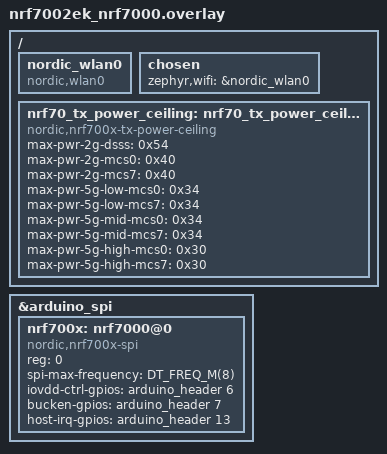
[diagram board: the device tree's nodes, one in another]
/* Copyright (c) 2023 Nordic Semiconductor ASA
 *
 * SPDX-License-Identifier: LicenseRef-Nordic-5-Clause
 */
#include <freq.h>

/ {
        nordic_wlan0: nordic_wlan0 {
                compatible = "nordic,wlan0";
                status = "okay";
        };

	chosen {
		zephyr,wifi = &nordic_wlan0;
	};

	nrf70_tx_power_ceiling: nrf70_tx_power_ceiling_node {
		status = "okay";
		compatible = "nordic,nrf700x-tx-power-ceiling";
		max-pwr-2g-dsss = <0x54>;
		max-pwr-2g-mcs0 = <0x40>;
		max-pwr-2g-mcs7 = <0x40>;
		max-pwr-5g-low-mcs0 = <0x34>;
		max-pwr-5g-low-mcs7 = <0x34>;
		max-pwr-5g-mid-mcs0 = <0x34>;
		max-pwr-5g-mid-mcs7 = <0x34>;
		max-pwr-5g-high-mcs0 = <0x30>;
		max-pwr-5g-high-mcs7 = <0x30>;
	};
};

&arduino_spi {
	status = "okay";

	nrf700x: nrf7000@0 {
		compatible = "nordic,nrf700x-spi";
		status = "okay";
		reg = <0>;
		spi-max-frequency = <DT_FREQ_M(8)>;

		iovdd-ctrl-gpios = <&arduino_header 6 (GPIO_ACTIVE_HIGH | GPIO_PULL_DOWN)>;    /* D0 */
		bucken-gpios = <&arduino_header 7 (GPIO_ACTIVE_HIGH | GPIO_PULL_DOWN)>;        /* D1 */
		host-irq-gpios = <&arduino_header 13 GPIO_ACTIVE_HIGH>;     /* D7 */
	};
};
